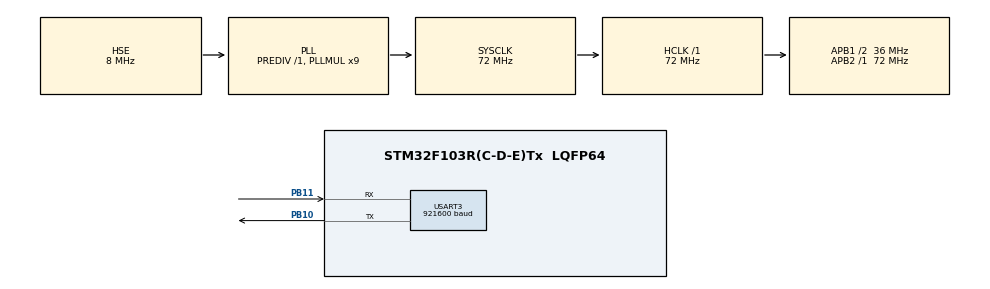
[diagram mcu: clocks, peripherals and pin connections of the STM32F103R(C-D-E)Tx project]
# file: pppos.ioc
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Dma.Request0=USART3_RX
Dma.Request1=USART3_TX
Dma.USART3_RX.0.Direction=DMA_PERIPH_TO_MEMORY
Dma.USART3_RX.0.Instance=DMA1_Channel3
Dma.USART3_RX.0.MemDataAlignment=DMA_MDATAALIGN_BYTE
Dma.USART3_RX.0.MemInc=DMA_MINC_ENABLE
Dma.USART3_RX.0.Mode=DMA_NORMAL
Dma.USART3_RX.0.PeriphDataAlignment=DMA_PDATAALIGN_BYTE
Dma.USART3_RX.0.PeriphInc=DMA_PINC_DISABLE
Dma.USART3_RX.0.Priority=DMA_PRIORITY_LOW
Dma.USART3_TX.1.Direction=DMA_MEMORY_TO_PERIPH
Dma.USART3_TX.1.Instance=DMA1_Channel2
Dma.USART3_TX.1.MemDataAlignment=DMA_MDATAALIGN_BYTE
Dma.USART3_TX.1.MemInc=DMA_MINC_ENABLE
Dma.USART3_TX.1.Mode=DMA_NORMAL
Dma.USART3_TX.1.PeriphDataAlignment=DMA_PDATAALIGN_BYTE
Dma.USART3_TX.1.PeriphInc=DMA_PINC_DISABLE
Dma.USART3_TX.1.Priority=DMA_PRIORITY_LOW
FREERTOS.Tasks01=defaultTask,0,128,StartDefaultTask,Default,NULL
FREERTOS.configTOTAL_HEAP_SIZE=20480
FREERTOS.configUSE_TIMERS=1
Mcu.Family=STM32F1
Mcu.Name=STM32F103R(C-D-E)Tx
Mcu.Package=LQFP64
NVIC.DMA1_Channel2_IRQn=true\:5\:0\:false\:true\:true\:3\:true\:false
NVIC.DMA1_Channel3_IRQn=true\:5\:0\:false\:true\:true\:2\:true\:false
NVIC.PriorityGroup=NVIC_PRIORITYGROUP_4
NVIC.USART3_IRQn=true\:5\:0\:false\:true\:true\:1\:true\:true
PA13.Mode=Trace_Asynchronous_SW
PA13.Signal=SYS_JTMS-SWDIO
PA14.Mode=Trace_Asynchronous_SW
PA14.Signal=SYS_JTCK-SWCLK
PB10.Mode=Asynchronous
PB10.Signal=USART3_TX
PB11.Mode=Asynchronous
PB11.Signal=USART3_RX
PB3.Mode=Trace_Asynchronous_SW
PB3.Signal=SYS_JTDO-TRACESWO
PD0-OSC_IN.Mode=HSE-External-Oscillator
PD0-OSC_IN.Signal=RCC_OSC_IN
PD1-OSC_OUT.Mode=HSE-External-Oscillator
PD1-OSC_OUT.Signal=RCC_OSC_OUT
ProjectManager.HeapSize=0x200
ProjectManager.StackSize=0x400
ProjectManager.TargetToolchain=MDK-ARM V5
RCC.AHBFreq_Value=72000000
RCC.APB1CLKDivider=RCC_HCLK_DIV2
RCC.APB1Freq_Value=36000000
RCC.APB1TimFreq_Value=72000000
RCC.APB2Freq_Value=72000000
RCC.APB2TimFreq_Value=72000000
RCC.HCLKFreq_Value=72000000
RCC.PLLMUL=RCC_PLL_MUL9
RCC.PLLSourceVirtual=RCC_PLLSOURCE_HSE
RCC.SYSCLKFreq_VALUE=72000000
RCC.SYSCLKSource=RCC_SYSCLKSOURCE_PLLCLK
RCC.USBFreq_Value=72000000
USART3.BaudRate=921600
USART3.VirtualMode=VM_ASYNC
VP_FREERTOS_VS_ENABLE.Mode=Enabled
board=pppos

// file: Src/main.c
/**
  ******************************************************************************
  * @file           : main.c
  * @brief          : Main program body
  ******************************************************************************
  * This notice applies to any and all portions of this file
  * that are not between comment pairs USER CODE BEGIN and
  * USER CODE END. Other portions of this file, whether
  * inserted by the user or by software development tools
  * are owned by their respective copyright owners.
  *
  * Copyright (c) 2018 STMicroelectronics International N.V.
  * All rights reserved.
  *
  * Redistribution and use in source and binary forms, with or without
  * modification, are permitted, provided that the following conditions are met:
  *
  * 1. Redistribution of source code must retain the above copyright notice,
  *    this list of conditions and the following disclaimer.
  * 2. Redistributions in binary form must reproduce the above copyright notice,
  *    this list of conditions and the following disclaimer in the documentation
  *    and/or other materials provided with the distribution.
  * 3. Neither the name of STMicroelectronics nor the names of other
  *    contributors to this software may be used to endorse or promote products
  *    derived from this software without specific written permission.
  * 4. This software, including modifications and/or derivative works of this
  *    software, must execute solely and exclusively on microcontroller or
  *    microprocessor devices manufactured by or for STMicroelectronics.
  * 5. Redistribution and use of this software other than as permitted under
  *    this license is void and will automatically terminate your rights under
  *    this license.
  *
  * THIS SOFTWARE IS PROVIDED BY STMICROELECTRONICS AND CONTRIBUTORS "AS IS"
  * AND ANY EXPRESS, IMPLIED OR STATUTORY WARRANTIES, INCLUDING, BUT NOT
  * LIMITED TO, THE IMPLIED WARRANTIES OF MERCHANTABILITY, FITNESS FOR A
  * PARTICULAR PURPOSE AND NON-INFRINGEMENT OF THIRD PARTY INTELLECTUAL PROPERTY
  * RIGHTS ARE DISCLAIMED TO THE FULLEST EXTENT PERMITTED BY LAW. IN NO EVENT
  * SHALL STMICROELECTRONICS OR CONTRIBUTORS BE LIABLE FOR ANY DIRECT, INDIRECT,
  * INCIDENTAL, SPECIAL, EXEMPLARY, OR CONSEQUENTIAL DAMAGES (INCLUDING, BUT NOT
  * LIMITED TO, PROCUREMENT OF SUBSTITUTE GOODS OR SERVICES; LOSS OF USE, DATA,
  * OR PROFITS; OR BUSINESS INTERRUPTION) HOWEVER CAUSED AND ON ANY THEORY OF
  * LIABILITY, WHETHER IN CONTRACT, STRICT LIABILITY, OR TORT (INCLUDING
  * NEGLIGENCE OR OTHERWISE) ARISING IN ANY WAY OUT OF THE USE OF THIS SOFTWARE,
  * EVEN IF ADVISED OF THE POSSIBILITY OF SUCH DAMAGE.
  *
  ******************************************************************************
  */
#include "main.h"
#include "stm32f1xx_hal.h"
#include "cmsis_os.h"
#include "dma.h"
#include "usart.h"
#include "gpio.h"

/* USER CODE BEGIN Includes */
#include "uart_driver.h"
/* USER CODE END Includes */

/* USER CODE BEGIN PV */
/* Private variables ---------------------------------------------------------*/

/* USER CODE END PV */

void SystemClock_Config(void);
void MX_FREERTOS_Init(void);
static void MX_NVIC_Init(void);

/* USER CODE BEGIN PFP */
/* Private function prototypes -----------------------------------------------*/

/* USER CODE END PFP */

int main(void)
{

  /* MCU Configuration----------------------------------------------------------*/

  /* Reset of all peripherals, Initializes the Flash interface and the Systick. */
  HAL_Init();

  /* USER CODE BEGIN Init */
    InitPeripherals();
  /* USER CODE END Init */

  /* Configure the system clock */
  SystemClock_Config();

  /* Initialize all configured peripherals */
  MX_GPIO_Init();
  MX_DMA_Init();
  MX_USART3_UART_Init();

  /* Initialize interrupts */
  MX_NVIC_Init();

  /* Call init function for freertos objects (in freertos.c) */
  MX_FREERTOS_Init();

  /* Start scheduler */
  osKernelStart();

  /* We should never get here as control is now taken by the scheduler */

  /* Infinite loop */
  while (1)
  {

  }

}

void SystemClock_Config(void)
{

  RCC_OscInitTypeDef RCC_OscInitStruct;
  RCC_ClkInitTypeDef RCC_ClkInitStruct;

    /**Initializes the CPU, AHB and APB busses clocks
    */
  RCC_OscInitStruct.OscillatorType = RCC_OSCILLATORTYPE_HSE;
  RCC_OscInitStruct.HSEState = RCC_HSE_ON;
  RCC_OscInitStruct.HSEPredivValue = RCC_HSE_PREDIV_DIV1;
  RCC_OscInitStruct.HSIState = RCC_HSI_ON;
  RCC_OscInitStruct.PLL.PLLState = RCC_PLL_ON;
  RCC_OscInitStruct.PLL.PLLSource = RCC_PLLSOURCE_HSE;
  RCC_OscInitStruct.PLL.PLLMUL = RCC_PLL_MUL9;
  if (HAL_RCC_OscConfig(&RCC_OscInitStruct) != HAL_OK)
  {
    _Error_Handler(__FILE__, __LINE__);
  }

    /**Initializes the CPU, AHB and APB busses clocks
    */
  RCC_ClkInitStruct.ClockType = RCC_CLOCKTYPE_HCLK|RCC_CLOCKTYPE_SYSCLK
                              |RCC_CLOCKTYPE_PCLK1|RCC_CLOCKTYPE_PCLK2;
  RCC_ClkInitStruct.SYSCLKSource = RCC_SYSCLKSOURCE_PLLCLK;
  RCC_ClkInitStruct.AHBCLKDivider = RCC_SYSCLK_DIV1;
  RCC_ClkInitStruct.APB1CLKDivider = RCC_HCLK_DIV2;
  RCC_ClkInitStruct.APB2CLKDivider = RCC_HCLK_DIV1;

  if (HAL_RCC_ClockConfig(&RCC_ClkInitStruct, FLASH_LATENCY_2) != HAL_OK)
  {
    _Error_Handler(__FILE__, __LINE__);
  }

    /**Configure the Systick interrupt time
    */
  HAL_SYSTICK_Config(HAL_RCC_GetHCLKFreq()/1000);

    /**Configure the Systick
    */
  HAL_SYSTICK_CLKSourceConfig(SYSTICK_CLKSOURCE_HCLK);

  /* SysTick_IRQn interrupt configuration */
  HAL_NVIC_SetPriority(SysTick_IRQn, 15, 0);
}

/**
  * @brief NVIC Configuration.
  * @retval None
  */
static void MX_NVIC_Init(void)
{
  /* USART3_IRQn interrupt configuration */
  HAL_NVIC_SetPriority(USART3_IRQn, 5, 0);
  HAL_NVIC_EnableIRQ(USART3_IRQn);
  /* DMA1_Channel3_IRQn interrupt configuration */
  HAL_NVIC_SetPriority(DMA1_Channel3_IRQn, 5, 0);
  HAL_NVIC_EnableIRQ(DMA1_Channel3_IRQn);
  /* DMA1_Channel2_IRQn interrupt configuration */
  HAL_NVIC_SetPriority(DMA1_Channel2_IRQn, 5, 0);
  HAL_NVIC_EnableIRQ(DMA1_Channel2_IRQn);
}

void _Error_Handler(char *file, int line)
{
  while(1)
  {
  }
}

/************************ (C) COPYRIGHT STMicroelectronics *****END OF FILE****/
